# MWPR1516 register map
Vendor: Freescale Semiconductor, Inc.; Series: Kinetis; File version: 1.6
CPU: CM0PLUS r0p0, little endian, no MPU, no FPU, VTOR, 2 interrupt priority bits
Registers are 8-bit, read-write, reset 0x0 unless marked. A register's access mark holds for its fields unless they carry their own. Offsets are from the block's base; [hi:lo] are bit positions; {n}, {i} and the like mark numbered series.

## CNC — Communication and Clamp Controller
Base 0x4006E000; register names take the prefix CNC_
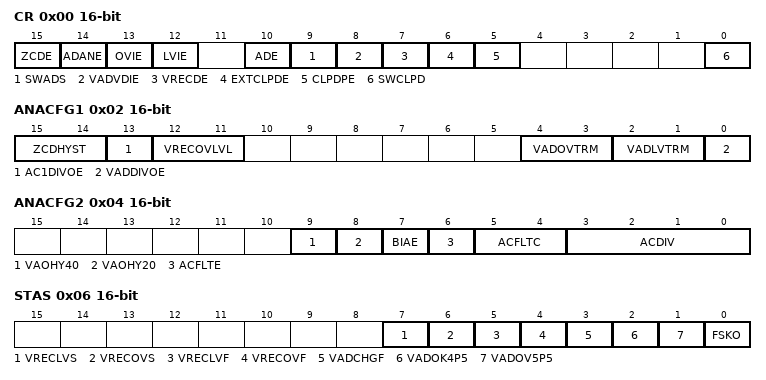
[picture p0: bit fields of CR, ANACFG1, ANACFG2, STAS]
0x00 CR 16-bit — Control Register
  [15] ZCDE — Zero-Crossing Detection Enable
    0=Zero-crossing detection is disabled; 1=Zero-crossing detection is enabled
  [14] ADANE — AD_IN Detection Enable
    0=Analog is disabled for AD_IN check; 1=Analog is enabled for AD_IN check
  [13] OVIE — VREC Overvoltage Interrupt Enable
    0=VREC overvoltage interrupt is disabled; 1=VREC overvoltage interrupt is enabled
  [12] LVIE — VREC Low Voltage Interrupt Enable
    0=VREC low voltage interrupt is disabled; 1=VREC low voltage interrupt is enabled
  [10] ADE — Adapter Switch Enable
    0=Adapter switch is disabled. The adapter switch is not enabled even when the plugged AD_IN voltage is valid.; 1=Adapter switch is enabled. When analog is enabled for AD_IN check and the plugged AD_IN is valid, the adapter switch is enabled.
  [9] SWADS — Software Adapter Switch
    0=Software does not assert the adapter switch; 1=Software asserts the adapter switch
  [8] VADVDIE — AD_IN Voltage Valid state change Interrupt Enable
    0=AD_IN voltage valid state change interrupt is disabled; 1=AD_IN voltage valid state change interrupt is enabled
  [7] VRECDE — VREC Detection Enable
    0=Analog is disabled for VREC range check; 1=Analog is enabled for VREC range check
  [6] EXTCLPDE — External Clamp Drive Enable
    0=External clamp drive is disabled; 1=External clamp drive is enabled
  [5] CLPDPE — Clamp Drive Port Enable
    0=The port for clamp drive is disabled; 1=The port for clamp drive is enabled
  [0] SWCLPD — Software sets Clamp Drive
    0=Software does not set clamp drive directly; 1=Clamp drive is set by software
0x02 ANACFG1 16-bit — Analog Configuration Register 1
  [15:14] ZCDHYST — Hysteresis control for FSK Zero-Crossing Detection
    {v}=Hysteresis level {v} (v=0..3)
  [13] AC1DIVOE — AC1 Divided Output Enable
    0=AC1 divided output is disabled; 1=AC1 divided output is enabled
  [12:11] VRECOVLVL — VREC Over Voltage Level Configuration
    {v}=Over-voltage level {v} (v=0..3)
  [4:3] VADOVTRM — Trim value set for the AD_IN overvoltage (VADOV5P5) detection
    {v}=Overvoltage threshold trim level {v} (v=0..3)
  [2:1] VADLVTRM — Trim value set for the AD_IN low voltage (VADOK4P5) detection
    {v}=Low voltage threshold trim level {v} (v=0..3)
  [0] VADDIVOE — AD_IN Divided Output Enable
    0=The AD_IN divided output is disabled; 1=The AD_IN divided output is enabled
0x04 ANACFG2 16-bit — Analog Configuration Register 2
  [9] VAOHY40 — 40 mV Hysteresis control for the comparator to compare AD_IN and VOUT
    0=There is no 40 mV hysteresis applied; 1=40 mV hysteresis is applied to the comparator
  [8] VAOHY20 — 20 mV Hysteresis control for the comparator to compare AD_IN and VOUT
    0=There is no 20 mV hysteresis applied; 1=20 mV hysteresis is applied to the comparator
  [7] BIAE — Bias Enable for the CNC module
    0=The current bias is disabled; 1=The current bias is enabled
  [6] ACFLTE — AC Filter Enable
    0=The AC filter is disabled; 1=The AC filter is enabled
  [5:4] ACFLTC — AC Filter Configuration
    0=AC filter configuration 0, the cut off frequency is 600 kHz; 1=AC filter configuration 1, the cut off frequency is 400 kHz; 2=AC filter configuration 2, the cut off frequency is 200 kHz; 3=AC filter configuration 3, the cut off frequency is 100 kHz
  [3:0] ACDIV — AC Divider selection
    0=The dividing ratio is 2/128; {v}=The dividing ratio is {v+3}/128 (v=1..10); 11=The dividing ratio is 15/128; 12=The dividing ratio is 16/128; 13=The dividing ratio is 17/128; 14=The dividing ratio is 19/128; 15=The dividing ratio is 21/128
0x06 STAS 16-bit — Status Register
  [7] VRECLVS ro — VREC Low Voltage State
  [6] VRECOVS ro — VREC Overvoltage State
  [5] VRECLVF — VREC Low Voltage Flag
  [4] VRECOVF — VREC Overvoltage Flag
  [3] VADCHGF — AD_IN Change status Flag
  [2] VADOK4P5 ro — AD_IN above 4.5 V state
  [1] VADOV5P5 ro — AD_IN above 5.5 V state
  [0] FSKO ro — FSK AC1/AC2 zero-crossing status
0x08 VRECOE 16-bit — VREC Overvoltage clamp drive Enable Register
  [0] VRECOVE — VREC Overvoltage clamp drive Enable
    0=VREC overvoltage is not enabled for the clamp drive; 1=VREC overvoltage is enabled for the clamp drive
0x0A VRECFLTC 16-bit — VREC Filter Control Register
  [15:0] CNT — Filter sample Count for VREC overvoltage or low voltage detection
    0=Filter is disabled
0x0C VADFLTC 16-bit — AD_IN Filter Control Register
  [15:0] CNT — Filter sample Count for AD_IN overvoltage or low voltage detection
    0=Filter is disabled
